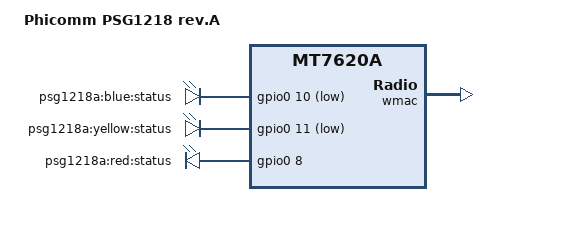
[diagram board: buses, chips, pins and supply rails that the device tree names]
/dts-v1/;

#include "PSG1218.dtsi"

/ {
	compatible = "phicomm,psg1218a", "phicomm,psg1218", "ralink,mt7620a-soc";
	model = "Phicomm PSG1218 rev.A";

	aliases {
		led-boot = &led_blue;
		led-failsafe = &led_blue;
		led-running = &led_blue;
		led-upgrade = &led_blue;
	};

	gpio-leds {
		compatible = "gpio-leds";
		led_blue: blue {
			label = "psg1218a:blue:status";
			gpios = <&gpio0 10 GPIO_ACTIVE_LOW>;
			default-state = "on";
		};

		yellow {
			label = "psg1218a:yellow:status";
			gpios = <&gpio0 11 GPIO_ACTIVE_LOW>;
			default-state = "off";
		};

		red {
			label = "psg1218a:red:status";
			gpios = <&gpio0 8 GPIO_ACTIVE_HIGH>;
			default-state = "off";
		};
	};
};

&pinctrl {
	state_default: pinctrl0 {
		gpio {
			ralink,group = "i2c", "uartf", "rgmii1", "rgmii2", "wled", "nd_sd";
			ralink,function = "gpio";
		};
	};
};

&ethernet {
	pinctrl-names = "default";
	pinctrl-0 = <&ephy_pins>;
	mtd-mac-address = <&factory 0x28>;
	mediatek,portmap = "llllw";
};

&wmac {
	pinctrl-names = "default";
	pinctrl-0 = <&pa_pins>;
};
